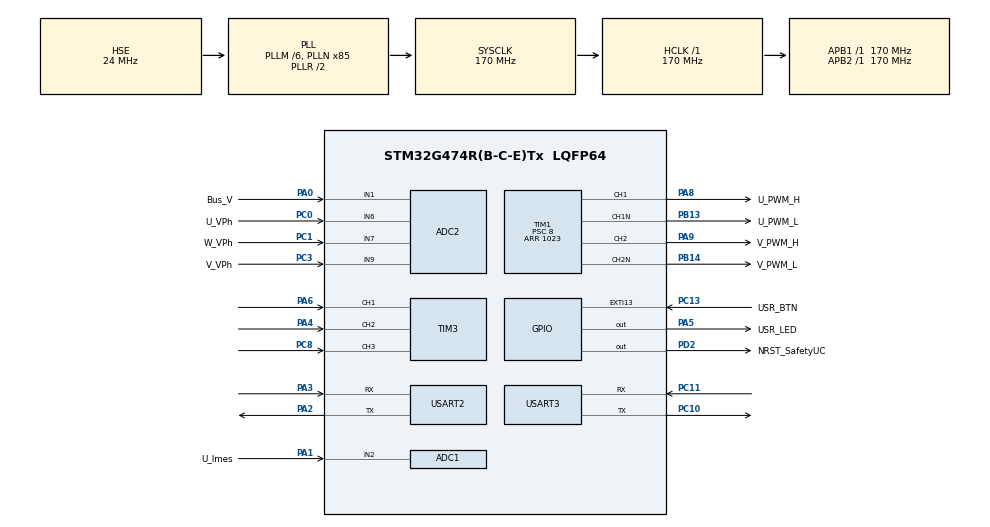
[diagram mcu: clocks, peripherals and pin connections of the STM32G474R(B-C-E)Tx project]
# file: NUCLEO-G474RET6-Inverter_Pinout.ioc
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ADC1.Channel-0\#ChannelRegularConversion=ADC_CHANNEL_2
ADC1.ClockPrescaler=ADC_CLOCK_SYNC_PCLK_DIV4
ADC1.ContinuousConvMode=DISABLE
ADC1.DMAContinuousRequests=ENABLE
ADC1.ExternalTrigConv=ADC_EXTERNALTRIG_T1_TRGO
ADC1.NbrOfConversion=1
ADC1.NbrOfConversionFlag=1
ADC1.OffsetNumber-0\#ChannelRegularConversion=ADC_OFFSET_NONE
ADC1.Rank-0\#ChannelRegularConversion=1
ADC1.SamplingTime-0\#ChannelRegularConversion=ADC_SAMPLETIME_92CYCLES_5
ADC1.master=1
ADC2.Channel-0\#ChannelRegularConversion=ADC_CHANNEL_1
ADC2.DMAContinuousRequests=ENABLE
ADC2.ExternalTrigConv=ADC_EXTERNALTRIG_T1_TRGO
ADC2.NbrOfConversionFlag=1
ADC2.OffsetNumber-0\#ChannelRegularConversion=ADC_OFFSET_NONE
ADC2.Rank-0\#ChannelRegularConversion=1
ADC2.SamplingTime-0\#ChannelRegularConversion=ADC_SAMPLETIME_92CYCLES_5
Dma.ADC1.0.Direction=DMA_PERIPH_TO_MEMORY
Dma.ADC1.0.EventEnable=DISABLE
Dma.ADC1.0.Instance=DMA1_Channel2
Dma.ADC1.0.MemDataAlignment=DMA_MDATAALIGN_HALFWORD
Dma.ADC1.0.MemInc=DMA_MINC_ENABLE
Dma.ADC1.0.Mode=DMA_CIRCULAR
Dma.ADC1.0.PeriphDataAlignment=DMA_PDATAALIGN_HALFWORD
Dma.ADC1.0.PeriphInc=DMA_PINC_DISABLE
Dma.ADC1.0.Polarity=HAL_DMAMUX_REQ_GEN_RISING
Dma.ADC1.0.Priority=DMA_PRIORITY_LOW
Dma.ADC1.0.RequestNumber=1
Dma.ADC1.0.SignalID=NONE
Dma.ADC1.0.SyncEnable=DISABLE
Dma.ADC1.0.SyncPolarity=HAL_DMAMUX_SYNC_NO_EVENT
Dma.ADC1.0.SyncRequestNumber=1
Dma.ADC1.0.SyncSignalID=NONE
Dma.ADC2.1.Direction=DMA_PERIPH_TO_MEMORY
Dma.ADC2.1.EventEnable=DISABLE
Dma.ADC2.1.Instance=DMA1_Channel1
Dma.ADC2.1.MemDataAlignment=DMA_MDATAALIGN_HALFWORD
Dma.ADC2.1.MemInc=DMA_MINC_ENABLE
Dma.ADC2.1.Mode=DMA_CIRCULAR
Dma.ADC2.1.PeriphDataAlignment=DMA_PDATAALIGN_HALFWORD
Dma.ADC2.1.PeriphInc=DMA_PINC_DISABLE
Dma.ADC2.1.Polarity=HAL_DMAMUX_REQ_GEN_RISING
Dma.ADC2.1.Priority=DMA_PRIORITY_LOW
Dma.ADC2.1.RequestNumber=1
Dma.ADC2.1.SignalID=NONE
Dma.ADC2.1.SyncEnable=DISABLE
Dma.ADC2.1.SyncPolarity=HAL_DMAMUX_SYNC_NO_EVENT
Dma.ADC2.1.SyncRequestNumber=1
Dma.ADC2.1.SyncSignalID=NONE
Dma.Request0=ADC1
Dma.Request1=ADC2
Mcu.Family=STM32G4
Mcu.Name=STM32G474R(B-C-E)Tx
Mcu.Package=LQFP64
NVIC.ADC1_2_IRQn=true\:0\:0\:false\:false\:true\:true\:true\:true
NVIC.DMA1_Channel1_IRQn=true\:0\:0\:false\:false\:true\:false\:true\:true
NVIC.DMA1_Channel2_IRQn=true\:0\:0\:false\:false\:true\:false\:true\:true
NVIC.EXTI15_10_IRQn=true\:0\:0\:false\:false\:true\:true\:true\:true
NVIC.PriorityGroup=NVIC_PRIORITYGROUP_4
NVIC.TIM6_DAC_IRQn=true\:15\:0\:false\:false\:true\:false\:true\:true
NVIC.TimeBase=TIM6_DAC_IRQn
NVIC.TimeBaseIP=TIM6
NVIC.USART2_IRQn=true\:0\:0\:false\:false\:true\:true\:true\:true
NVIC.USART3_IRQn=true\:0\:0\:false\:false\:true\:true\:true\:true
PA0.GPIO_Label=Bus_V
PA0.Mode=IN1-Single-Ended
PA0.Signal=ADC2_IN1
PA1.GPIO_Label=U_Imes
PA1.Mode=IN2-Single-Ended
PA1.Signal=ADC1_IN2
PA10.GPIO_Label=W_PWM_H
PA10.Signal=S_TIM1_CH3
PA13.GPIO_Label=T_SWDIO
PA13.Mode=Trace_Asynchronous_SW
PA13.Signal=SYS_JTMS-SWDIO
PA14.GPIO_Label=T_SWCLK
PA14.Mode=Trace_Asynchronous_SW
PA14.Signal=SYS_JTCK-SWCLK
PA2.Mode=Asynchronous
PA2.Signal=USART2_TX
PA3.Mode=Asynchronous
PA3.Signal=USART2_RX
PA4.Signal=S_TIM3_CH2
PA5.GPIO_Label=USR_LED
PA5.Signal=GPIO_Output
PA6.Signal=S_TIM3_CH1
PA8.GPIO_Label=U_PWM_H
PA8.Signal=S_TIM1_CH1
PA9.GPIO_Label=V_PWM_H
PA9.Signal=S_TIM1_CH2
PB0.Signal=ADC1_IN15
PB1.Signal=ADC1_IN12
PB13.GPIO_Label=U_PWM_L
PB13.Mode=PWM Generation1 CH1 CH1N
PB13.Signal=TIM1_CH1N
PB14.GPIO_Label=V_PWM_L
PB14.Mode=PWM Generation2 CH2 CH2N
PB14.Signal=TIM1_CH2N
PB15.GPIO_Label=W_PWM_L
PB15.Signal=TIM1_CH3N
PB3.GPIO_Label=T_SWO
PB3.Mode=Trace_Asynchronous_SW
PB3.Signal=SYS_JTDO-SWO
PC0.GPIO_Label=U_VPh
PC0.Mode=IN6-Single-Ended
PC0.Signal=ADC2_IN6
PC1.GPIO_Label=W_VPh
PC1.Mode=IN7-Single-Ended
PC1.Signal=ADC2_IN7
PC10.Mode=Asynchronous
PC10.Signal=USART3_TX
PC11.Mode=Asynchronous
PC11.Signal=USART3_RX
PC13.GPIO_Label=USR_BTN
PC13.Signal=GPXTI13
PC14-OSC32_IN.Mode=LSE-External-Oscillator
PC14-OSC32_IN.Signal=RCC_OSC32_IN
PC15-OSC32_OUT.Mode=LSE-External-Oscillator
PC15-OSC32_OUT.Signal=RCC_OSC32_OUT
PC2.GPIO_Label=Bus_Imes
PC2.Signal=ADC1_IN8
PC3.GPIO_Label=V_VPh
PC3.Mode=IN9-Single-Ended
PC3.Signal=ADC2_IN9
PC8.Signal=S_TIM3_CH3
PD2.GPIO_Label=NRST_SafetyUC
PD2.Signal=GPIO_Output
PF0-OSC_IN.Mode=HSE-External-Oscillator
PF0-OSC_IN.Signal=RCC_OSC_IN
PF1-OSC_OUT.Mode=HSE-External-Oscillator
PF1-OSC_OUT.Signal=RCC_OSC_OUT
ProjectManager.HeapSize=0x200
ProjectManager.StackSize=0x400
ProjectManager.TargetToolchain=STM32CubeIDE
RCC.ADC12Freq_Value=170000000
RCC.ADC345Freq_Value=170000000
RCC.AHBFreq_Value=170000000
RCC.APB1Freq_Value=170000000
RCC.APB1TimFreq_Value=170000000
RCC.APB2Freq_Value=170000000
RCC.APB2TimFreq_Value=170000000
RCC.CortexFreq_Value=170000000
RCC.EXTERNAL_CLOCK_VALUE=12288000
RCC.HCLKFreq_Value=170000000
RCC.HSE_VALUE=24000000
RCC.HSI48_VALUE=48000000
RCC.HSI_VALUE=16000000
RCC.PLLM=RCC_PLLM_DIV6
RCC.PLLN=85
RCC.PLLSourceVirtual=RCC_PLLSOURCE_HSE
RCC.RTCClockSelection=RCC_RTCCLKSOURCE_LSE
RCC.SYSCLKFreq_VALUE=170000000
RCC.SYSCLKSource=RCC_SYSCLKSOURCE_PLLCLK
RCC.USBFreq_Value=170000000
RCC.VCOOutputFreq_Value=340000000
SH.S_TIM1_CH1.0=TIM1_CH1,PWM Generation1 CH1 CH1N
SH.S_TIM1_CH2.0=TIM1_CH2,PWM Generation2 CH2 CH2N
SH.S_TIM1_CH3.0=TIM1_CH3
SH.S_TIM3_CH1.0=TIM3_CH1,Xored_Inputs_Hall_Sensor_Interface
SH.S_TIM3_CH2.0=TIM3_CH2,Xored_Inputs_Hall_Sensor_Interface
SH.S_TIM3_CH3.0=TIM3_CH3,Xored_Inputs_Hall_Sensor_Interface
TIM1.AsymmetricalDeadTime=DISABLE
TIM1.Channel-PWM\ Generation1\ CH1\ CH1N=TIM_CHANNEL_1
TIM1.Channel-PWM\ Generation2\ CH2\ CH2N=TIM_CHANNEL_2
TIM1.CounterMode=TIM_COUNTERMODE_CENTERALIGNED1
TIM1.DeadTime=33
TIM1.DeadTimePreload=ENABLE
TIM1.OCIdleState_2=TIM_OCIDLESTATE_RESET
TIM1.OCMode_PWM-PWM\ Generation2\ CH2\ CH2N=TIM_OCMODE_PWM1
TIM1.OCNPolarity_1=TIM_OCNPOLARITY_HIGH
TIM1.OCNPolarity_2=TIM_OCNPOLARITY_HIGH
TIM1.OCPolarity_1=TIM_OCPOLARITY_HIGH
TIM1.OCPolarity_2=TIM_OCPOLARITY_HIGH
TIM1.PeriodNoDither=1023
TIM1.Prescaler=8
TIM1.PulseNoDither_1=615
TIM1.PulseNoDither_2=1023-615
TIM1.TIM_MasterOutputTrigger=TIM_TRGO_UPDATE
TIM1.TIM_MasterSlaveMode=TIM_MASTERSLAVEMODE_DISABLE
USART2.VirtualMode-Asynchronous=VM_ASYNC
USART3.VirtualMode-Asynchronous=VM_ASYNC
VP_SYS_VS_DBSignals.Mode=DisableDeadBatterySignals
VP_SYS_VS_tim6.Mode=TIM6
VP_TIM1_VS_ClockSourceINT.Mode=Internal
board=NUCLEO-G474RE

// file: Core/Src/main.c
/* USER CODE BEGIN Header */
/**
 ******************************************************************************
 * @file           : main.c
 * @brief          : Main program body
 ******************************************************************************
 * @attention
 *
 * Copyright (c) 2023 STMicroelectronics.
 * All rights reserved.
 *
 * This software is licensed under terms that can be found in the LICENSE file
 * in the root directory of this software component.
 * If no LICENSE file comes with this software, it is provided AS-IS.
 *
 ******************************************************************************
 */
/* USER CODE END Header */
#include <measure2.h>
#include "main.h"

/* USER CODE BEGIN Includes */

#include "shell.h"
#include "motor.h"

/* USER CODE END Includes */

ADC_HandleTypeDef hadc1;
ADC_HandleTypeDef hadc2;
DMA_HandleTypeDef hdma_adc1;
DMA_HandleTypeDef hdma_adc2;

TIM_HandleTypeDef htim1;
TIM_HandleTypeDef htim3;

UART_HandleTypeDef huart2;
UART_HandleTypeDef huart3;

void SystemClock_Config(void);
static void MX_GPIO_Init(void);
static void MX_DMA_Init(void);
static void MX_ADC2_Init(void);
static void MX_ADC1_Init(void);
static void MX_TIM1_Init(void);
static void MX_TIM3_Init(void);
static void MX_USART2_UART_Init(void);
static void MX_USART3_UART_Init(void);

/* USER CODE BEGIN 0 */

// récupération du courant et de la vitesse

/* USER CODE END 0 */

int main(void)
{
  /* USER CODE BEGIN 1 */

	uint32_t 	period = __HAL_TIM_GET_AUTORELOAD(&htim1);
	uint32_t 	pulse_value = __HAL_TIM_GET_COMPARE(&htim1, TIM_CHANNEL_1);

  /* USER CODE END 1 */

  /* MCU Configuration--------------------------------------------------------*/

  /* Reset of all peripherals, Initializes the Flash interface and the Systick. */
  HAL_Init();

  /* Configure the system clock */
  SystemClock_Config();

  /* Initialize all configured peripherals */
  MX_GPIO_Init();
  MX_DMA_Init();
  MX_ADC2_Init();
  MX_ADC1_Init();
  MX_TIM1_Init();
  MX_TIM3_Init();
  MX_USART2_UART_Init();
  MX_USART3_UART_Init();
  /* USER CODE BEGIN 2 */

	//	HAL_ADC_Start(&hadc1);
	//	HAL_ADC_PollForConversion(&hadc1, HAL_MAX_DELAY);

	// Démarrage du Timer en mode TRGO
	HAL_TIM_Base_Start(&htim1);
	StartShell();
	StartADC();
  /* USER CODE END 2 */

  /* Infinite loop */
  /* USER CODE BEGIN WHILE */
	while (1)
	{
		// uartRxReceived is set to 1 when a new character is received on uart 1
		Shell_Process();
		New_Command();
    /* USER CODE END WHILE */

	}
}

void SystemClock_Config(void)
{
  RCC_OscInitTypeDef RCC_OscInitStruct = {0};
  RCC_ClkInitTypeDef RCC_ClkInitStruct = {0};

  /** Configure the main internal regulator output voltage
  */
  HAL_PWREx_ControlVoltageScaling(PWR_REGULATOR_VOLTAGE_SCALE1_BOOST);

  /** Initializes the RCC Oscillators according to the specified parameters
  * in the RCC_OscInitTypeDef structure.
  */
  RCC_OscInitStruct.OscillatorType = RCC_OSCILLATORTYPE_HSE;
  RCC_OscInitStruct.HSEState = RCC_HSE_ON;
  RCC_OscInitStruct.PLL.PLLState = RCC_PLL_ON;
  RCC_OscInitStruct.PLL.PLLSource = RCC_PLLSOURCE_HSE;
  RCC_OscInitStruct.PLL.PLLM = RCC_PLLM_DIV6;
  RCC_OscInitStruct.PLL.PLLN = 85;
  RCC_OscInitStruct.PLL.PLLP = RCC_PLLP_DIV2;
  RCC_OscInitStruct.PLL.PLLQ = RCC_PLLQ_DIV2;
  RCC_OscInitStruct.PLL.PLLR = RCC_PLLR_DIV2;
  if (HAL_RCC_OscConfig(&RCC_OscInitStruct) != HAL_OK)
  {
    Error_Handler();
  }

  /** Initializes the CPU, AHB and APB buses clocks
  */
  RCC_ClkInitStruct.ClockType = RCC_CLOCKTYPE_HCLK|RCC_CLOCKTYPE_SYSCLK
                              |RCC_CLOCKTYPE_PCLK1|RCC_CLOCKTYPE_PCLK2;
  RCC_ClkInitStruct.SYSCLKSource = RCC_SYSCLKSOURCE_PLLCLK;
  RCC_ClkInitStruct.AHBCLKDivider = RCC_SYSCLK_DIV1;
  RCC_ClkInitStruct.APB1CLKDivider = RCC_HCLK_DIV1;
  RCC_ClkInitStruct.APB2CLKDivider = RCC_HCLK_DIV1;

  if (HAL_RCC_ClockConfig(&RCC_ClkInitStruct, FLASH_LATENCY_4) != HAL_OK)
  {
    Error_Handler();
  }
}

static void MX_ADC1_Init(void)
{

  ADC_MultiModeTypeDef multimode = {0};
  ADC_ChannelConfTypeDef sConfig = {0};

  /** Common config
  */
  hadc1.Instance = ADC1;
  hadc1.Init.ClockPrescaler = ADC_CLOCK_SYNC_PCLK_DIV4;
  hadc1.Init.Resolution = ADC_RESOLUTION_12B;
  hadc1.Init.DataAlign = ADC_DATAALIGN_RIGHT;
  hadc1.Init.GainCompensation = 0;
  hadc1.Init.ScanConvMode = ADC_SCAN_DISABLE;
  hadc1.Init.EOCSelection = ADC_EOC_SINGLE_CONV;
  hadc1.Init.LowPowerAutoWait = DISABLE;
  hadc1.Init.ContinuousConvMode = DISABLE;
  hadc1.Init.NbrOfConversion = 1;
  hadc1.Init.DiscontinuousConvMode = DISABLE;
  hadc1.Init.ExternalTrigConv = ADC_EXTERNALTRIG_T1_TRGO;
  hadc1.Init.ExternalTrigConvEdge = ADC_EXTERNALTRIGCONVEDGE_RISING;
  hadc1.Init.DMAContinuousRequests = ENABLE;
  hadc1.Init.Overrun = ADC_OVR_DATA_PRESERVED;
  hadc1.Init.OversamplingMode = DISABLE;
  if (HAL_ADC_Init(&hadc1) != HAL_OK)
  {
    Error_Handler();
  }

  /** Configure the ADC multi-mode
  */
  multimode.Mode = ADC_MODE_INDEPENDENT;
  if (HAL_ADCEx_MultiModeConfigChannel(&hadc1, &multimode) != HAL_OK)
  {
    Error_Handler();
  }

  /** Configure Regular Channel
  */
  sConfig.Channel = ADC_CHANNEL_2;
  sConfig.Rank = ADC_REGULAR_RANK_1;
  sConfig.SamplingTime = ADC_SAMPLETIME_92CYCLES_5;
  sConfig.SingleDiff = ADC_SINGLE_ENDED;
  sConfig.OffsetNumber = ADC_OFFSET_NONE;
  sConfig.Offset = 0;
  if (HAL_ADC_ConfigChannel(&hadc1, &sConfig) != HAL_OK)
  {
    Error_Handler();
  }

}

static void MX_ADC2_Init(void)
{

  ADC_ChannelConfTypeDef sConfig = {0};

  /** Common config
  */
  hadc2.Instance = ADC2;
  hadc2.Init.ClockPrescaler = ADC_CLOCK_SYNC_PCLK_DIV4;
  hadc2.Init.Resolution = ADC_RESOLUTION_12B;
  hadc2.Init.DataAlign = ADC_DATAALIGN_RIGHT;
  hadc2.Init.GainCompensation = 0;
  hadc2.Init.ScanConvMode = ADC_SCAN_DISABLE;
  hadc2.Init.EOCSelection = ADC_EOC_SINGLE_CONV;
  hadc2.Init.LowPowerAutoWait = DISABLE;
  hadc2.Init.ContinuousConvMode = DISABLE;
  hadc2.Init.NbrOfConversion = 1;
  hadc2.Init.DiscontinuousConvMode = DISABLE;
  hadc2.Init.ExternalTrigConv = ADC_EXTERNALTRIG_T1_TRGO;
  hadc2.Init.ExternalTrigConvEdge = ADC_EXTERNALTRIGCONVEDGE_RISING;
  hadc2.Init.DMAContinuousRequests = ENABLE;
  hadc2.Init.Overrun = ADC_OVR_DATA_PRESERVED;
  hadc2.Init.OversamplingMode = DISABLE;
  if (HAL_ADC_Init(&hadc2) != HAL_OK)
  {
    Error_Handler();
  }

  /** Configure Regular Channel
  */
  sConfig.Channel = ADC_CHANNEL_1;
  sConfig.Rank = ADC_REGULAR_RANK_1;
  sConfig.SamplingTime = ADC_SAMPLETIME_92CYCLES_5;
  sConfig.SingleDiff = ADC_SINGLE_ENDED;
  sConfig.OffsetNumber = ADC_OFFSET_NONE;
  sConfig.Offset = 0;
  if (HAL_ADC_ConfigChannel(&hadc2, &sConfig) != HAL_OK)
  {
    Error_Handler();
  }

}

static void MX_TIM1_Init(void)
{

  TIM_ClockConfigTypeDef sClockSourceConfig = {0};
  TIM_MasterConfigTypeDef sMasterConfig = {0};
  TIM_OC_InitTypeDef sConfigOC = {0};
  TIM_BreakDeadTimeConfigTypeDef sBreakDeadTimeConfig = {0};

  htim1.Instance = TIM1;
  htim1.Init.Prescaler = 8;
  htim1.Init.CounterMode = TIM_COUNTERMODE_CENTERALIGNED1;
  htim1.Init.Period = 1023;
  htim1.Init.ClockDivision = TIM_CLOCKDIVISION_DIV1;
  htim1.Init.RepetitionCounter = 0;
  htim1.Init.AutoReloadPreload = TIM_AUTORELOAD_PRELOAD_DISABLE;
  if (HAL_TIM_Base_Init(&htim1) != HAL_OK)
  {
    Error_Handler();
  }
  sClockSourceConfig.ClockSource = TIM_CLOCKSOURCE_INTERNAL;
  if (HAL_TIM_ConfigClockSource(&htim1, &sClockSourceConfig) != HAL_OK)
  {
    Error_Handler();
  }
  if (HAL_TIM_PWM_Init(&htim1) != HAL_OK)
  {
    Error_Handler();
  }
  sMasterConfig.MasterOutputTrigger = TIM_TRGO_UPDATE;
  sMasterConfig.MasterOutputTrigger2 = TIM_TRGO2_RESET;
  sMasterConfig.MasterSlaveMode = TIM_MASTERSLAVEMODE_DISABLE;
  if (HAL_TIMEx_MasterConfigSynchronization(&htim1, &sMasterConfig) != HAL_OK)
  {
    Error_Handler();
  }
  sConfigOC.OCMode = TIM_OCMODE_PWM1;
  sConfigOC.Pulse = 615;
  sConfigOC.OCPolarity = TIM_OCPOLARITY_HIGH;
  sConfigOC.OCNPolarity = TIM_OCNPOLARITY_HIGH;
  sConfigOC.OCFastMode = TIM_OCFAST_DISABLE;
  sConfigOC.OCIdleState = TIM_OCIDLESTATE_RESET;
  sConfigOC.OCNIdleState = TIM_OCNIDLESTATE_RESET;
  if (HAL_TIM_PWM_ConfigChannel(&htim1, &sConfigOC, TIM_CHANNEL_1) != HAL_OK)
  {
    Error_Handler();
  }
  sConfigOC.Pulse = 408;
  if (HAL_TIM_PWM_ConfigChannel(&htim1, &sConfigOC, TIM_CHANNEL_2) != HAL_OK)
  {
    Error_Handler();
  }
  HAL_TIMEx_EnableDeadTimePreload(&htim1);
  sBreakDeadTimeConfig.OffStateRunMode = TIM_OSSR_DISABLE;
  sBreakDeadTimeConfig.OffStateIDLEMode = TIM_OSSI_DISABLE;
  sBreakDeadTimeConfig.LockLevel = TIM_LOCKLEVEL_OFF;
  sBreakDeadTimeConfig.DeadTime = 33;
  sBreakDeadTimeConfig.BreakState = TIM_BREAK_DISABLE;
  sBreakDeadTimeConfig.BreakPolarity = TIM_BREAKPOLARITY_HIGH;
  sBreakDeadTimeConfig.BreakFilter = 0;
  sBreakDeadTimeConfig.BreakAFMode = TIM_BREAK_AFMODE_INPUT;
  sBreakDeadTimeConfig.Break2State = TIM_BREAK2_DISABLE;
  sBreakDeadTimeConfig.Break2Polarity = TIM_BREAK2POLARITY_HIGH;
  sBreakDeadTimeConfig.Break2Filter = 0;
  sBreakDeadTimeConfig.Break2AFMode = TIM_BREAK_AFMODE_INPUT;
  sBreakDeadTimeConfig.AutomaticOutput = TIM_AUTOMATICOUTPUT_DISABLE;
  if (HAL_TIMEx_ConfigBreakDeadTime(&htim1, &sBreakDeadTimeConfig) != HAL_OK)
  {
    Error_Handler();
  }
  HAL_TIM_MspPostInit(&htim1);

}

static void MX_TIM3_Init(void)
{

  TIM_HallSensor_InitTypeDef sConfig = {0};
  TIM_MasterConfigTypeDef sMasterConfig = {0};

  htim3.Instance = TIM3;
  htim3.Init.Prescaler = 0;
  htim3.Init.CounterMode = TIM_COUNTERMODE_UP;
  htim3.Init.Period = 65535;
  htim3.Init.ClockDivision = TIM_CLOCKDIVISION_DIV1;
  htim3.Init.AutoReloadPreload = TIM_AUTORELOAD_PRELOAD_DISABLE;
  sConfig.IC1Polarity = TIM_ICPOLARITY_RISING;
  sConfig.IC1Prescaler = TIM_ICPSC_DIV1;
  sConfig.IC1Filter = 0;
  sConfig.Commutation_Delay = 0;
  if (HAL_TIMEx_HallSensor_Init(&htim3, &sConfig) != HAL_OK)
  {
    Error_Handler();
  }
  sMasterConfig.MasterOutputTrigger = TIM_TRGO_OC2REF;
  sMasterConfig.MasterSlaveMode = TIM_MASTERSLAVEMODE_DISABLE;
  if (HAL_TIMEx_MasterConfigSynchronization(&htim3, &sMasterConfig) != HAL_OK)
  {
    Error_Handler();
  }

}

static void MX_USART2_UART_Init(void)
{

  huart2.Instance = USART2;
  huart2.Init.BaudRate = 115200;
  huart2.Init.WordLength = UART_WORDLENGTH_8B;
  huart2.Init.StopBits = UART_STOPBITS_1;
  huart2.Init.Parity = UART_PARITY_NONE;
  huart2.Init.Mode = UART_MODE_TX_RX;
  huart2.Init.HwFlowCtl = UART_HWCONTROL_NONE;
  huart2.Init.OverSampling = UART_OVERSAMPLING_16;
  huart2.Init.OneBitSampling = UART_ONE_BIT_SAMPLE_DISABLE;
  huart2.Init.ClockPrescaler = UART_PRESCALER_DIV1;
  huart2.AdvancedInit.AdvFeatureInit = UART_ADVFEATURE_NO_INIT;
  if (HAL_UART_Init(&huart2) != HAL_OK)
  {
    Error_Handler();
  }
  if (HAL_UARTEx_SetTxFifoThreshold(&huart2, UART_TXFIFO_THRESHOLD_1_8) != HAL_OK)
  {
    Error_Handler();
  }
  if (HAL_UARTEx_SetRxFifoThreshold(&huart2, UART_RXFIFO_THRESHOLD_1_8) != HAL_OK)
  {
    Error_Handler();
  }
  if (HAL_UARTEx_DisableFifoMode(&huart2) != HAL_OK)
  {
    Error_Handler();
  }

}

static void MX_USART3_UART_Init(void)
{

  huart3.Instance = USART3;
  huart3.Init.BaudRate = 115200;
  huart3.Init.WordLength = UART_WORDLENGTH_8B;
  huart3.Init.StopBits = UART_STOPBITS_1;
  huart3.Init.Parity = UART_PARITY_NONE;
  huart3.Init.Mode = UART_MODE_TX_RX;
  huart3.Init.HwFlowCtl = UART_HWCONTROL_NONE;
  huart3.Init.OverSampling = UART_OVERSAMPLING_16;
  huart3.Init.OneBitSampling = UART_ONE_BIT_SAMPLE_DISABLE;
  huart3.Init.ClockPrescaler = UART_PRESCALER_DIV1;
  huart3.AdvancedInit.AdvFeatureInit = UART_ADVFEATURE_NO_INIT;
  if (HAL_UART_Init(&huart3) != HAL_OK)
  {
    Error_Handler();
  }
  if (HAL_UARTEx_SetTxFifoThreshold(&huart3, UART_TXFIFO_THRESHOLD_1_8) != HAL_OK)
  {
    Error_Handler();
  }
  if (HAL_UARTEx_SetRxFifoThreshold(&huart3, UART_RXFIFO_THRESHOLD_1_8) != HAL_OK)
  {
    Error_Handler();
  }
  if (HAL_UARTEx_DisableFifoMode(&huart3) != HAL_OK)
  {
    Error_Handler();
  }

}

static void MX_DMA_Init(void)
{

  /* DMA controller clock enable */
  __HAL_RCC_DMAMUX1_CLK_ENABLE();
  __HAL_RCC_DMA1_CLK_ENABLE();

  /* DMA interrupt init */
  /* DMA1_Channel1_IRQn interrupt configuration */
  HAL_NVIC_SetPriority(DMA1_Channel1_IRQn, 0, 0);
  HAL_NVIC_EnableIRQ(DMA1_Channel1_IRQn);
  /* DMA1_Channel2_IRQn interrupt configuration */
  HAL_NVIC_SetPriority(DMA1_Channel2_IRQn, 0, 0);
  HAL_NVIC_EnableIRQ(DMA1_Channel2_IRQn);

}

static void MX_GPIO_Init(void)
{
  GPIO_InitTypeDef GPIO_InitStruct = {0};

  /* GPIO Ports Clock Enable */
  __HAL_RCC_GPIOC_CLK_ENABLE();
  __HAL_RCC_GPIOF_CLK_ENABLE();
  __HAL_RCC_GPIOA_CLK_ENABLE();
  __HAL_RCC_GPIOB_CLK_ENABLE();
  __HAL_RCC_GPIOD_CLK_ENABLE();

  /*Configure GPIO pin Output Level */
  HAL_GPIO_WritePin(USR_LED_GPIO_Port, USR_LED_Pin, GPIO_PIN_RESET);

  /*Configure GPIO pin Output Level */
  HAL_GPIO_WritePin(NRST_SafetyUC_GPIO_Port, NRST_SafetyUC_Pin, GPIO_PIN_RESET);

  /*Configure GPIO pin : USR_BTN_Pin */
  GPIO_InitStruct.Pin = USR_BTN_Pin;
  GPIO_InitStruct.Mode = GPIO_MODE_IT_RISING;
  GPIO_InitStruct.Pull = GPIO_NOPULL;
  HAL_GPIO_Init(USR_BTN_GPIO_Port, &GPIO_InitStruct);

  /*Configure GPIO pin : USR_LED_Pin */
  GPIO_InitStruct.Pin = USR_LED_Pin;
  GPIO_InitStruct.Mode = GPIO_MODE_OUTPUT_PP;
  GPIO_InitStruct.Pull = GPIO_NOPULL;
  GPIO_InitStruct.Speed = GPIO_SPEED_FREQ_LOW;
  HAL_GPIO_Init(USR_LED_GPIO_Port, &GPIO_InitStruct);

  /*Configure GPIO pin : NRST_SafetyUC_Pin */
  GPIO_InitStruct.Pin = NRST_SafetyUC_Pin;
  GPIO_InitStruct.Mode = GPIO_MODE_OUTPUT_PP;
  GPIO_InitStruct.Pull = GPIO_NOPULL;
  GPIO_InitStruct.Speed = GPIO_SPEED_FREQ_LOW;
  HAL_GPIO_Init(NRST_SafetyUC_GPIO_Port, &GPIO_InitStruct);

  /* EXTI interrupt init*/
  HAL_NVIC_SetPriority(EXTI15_10_IRQn, 0, 0);
  HAL_NVIC_EnableIRQ(EXTI15_10_IRQn);

}

void HAL_TIM_PeriodElapsedCallback(TIM_HandleTypeDef *htim)
{
  if (htim->Instance == TIM6) {
    HAL_IncTick();
  }
}

void Error_Handler(void)
{
	__disable_irq();
	while (1)
	{
	}
}
